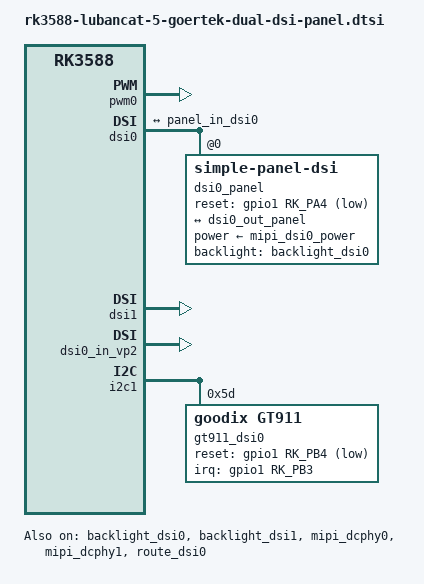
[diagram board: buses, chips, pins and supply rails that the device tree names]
// SPDX-License-Identifier: (GPL-2.0+ OR MIT)
/*
 * Copyright (c) 2021 Rockchip Electronics Co., Ltd.
 *
 */

&pwm0 {
	pinctrl-0 = <&pwm0m0_pins>;
	status = "okay";
};

&backlight_dsi0 {
	status = "okay";
};

&backlight_dsi1 {
	status = "okay";
};

&dsi0 {
	status = "okay";
	//rockchip,data-swap;
	rockchip,dual-channel = <&dsi1>;
    	rockchip,lane-rate = <400000>;
    	
	dsi0_panel: panel@0 {
        	status = "okay";
		compatible = "simple-panel-dsi";
		reg = <0>;
		backlight = <&backlight_dsi0>;
		power-supply = <&mipi_dsi0_power>;
		reset-gpios = <&gpio1 RK_PA4 GPIO_ACTIVE_LOW>;
		bpc = <8>;
		bus-format = <MEDIA_BUS_FMT_RGB888_1X24>;

		enable-delay-ms = <35>;
		prepare-delay-ms = <6>;
		reset-delay-ms = <2000>;
		init-delay-ms = <3000>;
		unprepare-delay-ms = <0>;
		disable-delay-ms = <20>;

		//size,width = <74>;
		//size,height = <133>;

		dsi,flags = <(MIPI_DSI_MODE_VIDEO | MIPI_DSI_MODE_VIDEO_BURST | MIPI_DSI_CLOCK_NON_CONTINUOUS | 
		MIPI_DSI_MODE_LPM)>;
        	dsi,format = <MIPI_DSI_FMT_RGB888>;
        	dsi,lanes  = <8>;

        panel-init-sequence = [

			39 00 02 B0 00
39 00 02 FF 00

39 00 5F F5 12 00 00 89 30 80 0f 00 0d e0 00 18 03 78 03 78 02 00 02 e1 00 20 02 b9 00 0c 00 0d 04 86 02 94 18 00 10 f0 03 0c 20 00 06 0b 0b 33 0e 1c 2a 38 46 54 62 69 70 77 79 7b 7d 7e 01 02 01 00 09 40 09 be 19 fc 19 fa 19 f8 1a 38 1a 78 1a b6 2a b6 2a f4 2a f4 4b 34 63 74 00 00 00 00 00 00
39 00 5F F6 11 00 00 AB 10 A0 0A 00 05 A0 00 20 02 D0 03 84 01 9A 02 68 00 19 02 D9 00 0E 00 0F 03 DF 02 EB 16 00 10 EC 07 10 20 00 06 0F 0F 33 0E 1C 2A 38 46 54 62 69 70 77 79 7B 7D 7E 01 C2 22 00 2A 40 2A BE 3A FC 3A FA 3A F8 3B 38 3B 78 3B 76 4B B6 4B B6 4B F4 63 F4 7C 34 00 00 00 00 00 00
39 00 5F F7 11 00 00 89 10 80 0A 00 05 A0 00 20 02 D0 02 D0 02 00 02 68 00 20 03 87 00 0A 00 0C 03 19 02 63 18 00 10 F0 03 0C 20 00 06 0B 0B 33 0E 1C 2A 38 46 54 62 69 70 77 79 7B 7D 7E 01 02 01 00 09 40 09 BE 19 FC 19 FA 19 F8 1A 38 1A 78 1A B6 2A F6 2B 34 2B 74 3B 74 6B F4 00 00 00 00 00 00
39 00 5F F8 11 00 00 AB 10 A0 0A 00 05 A0 00 20 02 D0 03 84 01 9A 02 68 00 19 02 D9 00 0E 00 0F 03 DF 02 EB 16 00 10 EC 07 10 20 00 06 0F 0F 33 0E 1C 2A 38 46 54 62 69 70 77 79 7B 7D 7E 01 C2 22 00 2A 40 2A BE 3A FC 3A FA 3A F8 3B 38 3B 78 3B 76 4B B6 4B B6 4B F4 63 F4 7C 34 00 00 00 00 00 00
39 00 1C B1 00 18 19 00 18 18 00 18 18 00 18 18 00 18 18 00 18 18 00 18 18 00 18 18 00 18 19
39 00 13 B2 0F 00 0F 00 0F 00 0F 00 0F 00 0F 00 0F 00 0F 00 0F 00
39 00 03 B4 00 BA
39 00 08 B5 11 11 00 01 25 00 EB

39 00 02 B7 93
39 00 02 B8 06
39 00 02 BA 8C
39 00 02 BB 01
39 00 03 BC 00 00
39 00 15 C7 00 00 FF FF 01 03 FF 03 FF 03 FF 00 00 00 00 00 00 00 00 00
39 00 09 C8 10 32 54 76 98 BA DC 0E

39 00 02 FF 01
39 00 15 B1 30 6C 06 FF FF 00 00 48 A3 6B 00 92 03 1A D0 09 00 00 00 08
39 00 04 B2 00 00 00
39 00 BC B5 11 11 10 33 33 33 33 33 FF FF FF 6C 00 00 FF FF FF FF F0 01 00 FB 00 00 00 AA FA 1B 03 20 00 40 00 00 03 10 51 51 10 04 10 03 11 10 04 10 03 10 04 10 03 11 10 03 10 03 00 00 00 00 10 01 10 01 00 00 00 1F FF 00 00 10 01 10 01 00 00 00 1F FF 00 00 00 10 01 10 01 00 80 00 1F FF 00 00 00 10 01 10 01 00 00 00 1F FF 00 00 00 10 01 10 01 00 00 00 1F FF 00 00 10 01 10 01 00 00 00 1F FF 01 00 10 01 10 01 00 00 00 00 00 00 00 10 01 10 01 00 00 00 00 00 00 00 00 00 02 00 00 02 00 00 02 00 00 02 00 00 02 00 00 02 00 00 02 00 00 02 00 00 00 00 00 00 00 00 00 00 00 00
39 00 55 B6 B0 00 00 00 00 00 80 04 0A F0 01 00 00 20 20 00 00 00 00 00 00 00 00 00 00 00 03 05 84 97 8B 00 00 21 00 21 00 21 00 21 00 21 00 21 00 40 00 00 00 00 00 00 00 00 00 00 00 00 00 00 00 00 00 00 00 00 00 00 00 00 03 28 00 14 00 14 00 14 00 14 00 14 00 14
39 00 5D B7 00 00 00 02 00 00 40 05 00 00 88 88 88 88 00 00 00 00 00 00 00 00 00 00 00 00 00 00 00 00 00 00 00 00 00 00 00 00 00 A8 A8 A8 A8 A8 A8 A8 A8 00 FF AA 00 09 10 00 00 00 00 00 00 00 11 11 11 11 11 11 11 11 11 11 11 11 A0 00 00 10 09 C4 01 0A 0A 03 c9 00 00 00 06 7C 28 06 7C 28
39 00 77 BA 00 00 00 00 20 02 6C 10 00 00 00 00 00 00 00 6C 10 00 00 00 00 01 50 17 00 10 00 00 00 00 00 00 00 00 00 00 00 00 00 00 00 00 00 00 00 00 00 00 00 0F FF 00 00 00 00 00 00 00 0F 10 00 10 00 00 00 00 01 B3 20 00 10 00 00 00 00 02 00 00 02 00 00 02 00 00 02 00 00 02 00 00 02 00 00 02 00 00 02 00 00 00 00 00 00 00 00 00 00 00 00 00 00 00 00 00 00 00 00 00
39 00 78 BB 3f fd 00 1f 3f f0 00 03 3f fc 00 0f 3f fc 00 0f 3f fc 00 0f 3f fc 00 0f 3f f0 00 03 3f fc 00 0f 00 00 00 00 00 00 00 00 00 00 00 00 00 00 00 00 00 00 00 00 00 3f fc 00 0f 3f fc 00 0f 3f fc 00 0f 3f fc 00 0f 3f fc 00 0f 3f fc 00 0f 3f fc 00 0f 3f fd 15 5f 3f fc 00 0f 3f fc 00 0f 3f fc 00 0f 3f fc 00 0f 03 c0 00 0f 00 00 48 00 00 01 00 09 3f fc 00 0F 00 00
39 00 21 BE 00 00 00 00 00 07 00 00 00 00 00 00 00 00 00 00 50 AA AA AA AA AA AA 90 00 AA AA AA AA AA AA 90
39 00 8C BF 46 48 4A 4C 4E 50 02 06 0A 0E 12 16 1A 1E 22 2A 01 01 01 01 3C 41 00 00 01 01 33 00 01 01 46 48 4A 4C 4E 50 02 06 0A 0E 12 16 1A 1E 22 2A 01 01 01 01 3C 41 00 00 01 01 33 01 01 01 00 00 00 00 00 00 00 00 00 00 00 00 00 00 00 00 00 00 00 00 00 00 00 00 FF FF FF FF FF FF FF 0F 3F 00 01 00 00 08 C0 0F 00 20 00 00 00 08 00 00 80 00 00 00 00 00 00 00 00 00 00 00 00 00 00 00 00 00 00 00 00 00 00 00 00 00 00 00 00 00 00
39 00 69 C0 03 E8 03 E8 03 E8 00 07 00 07 00 07 03 E8 03 E8 03 E8 00 07 00 07 00 07 03 E8 03 E8 03 E8 00 07 00 07 00 07 03 E8 03 E8 03 E8 00 07 00 07 00 07 00 00 00 29 00 17 00 17 00 17 00 17 00 17 00 17 00 00 00 00 00 00 00 00 00 00 00 00 00 00 00 2B 00 16 00 16 00 16 00 16 00 16 00 08 00 00 00 00 00 00 00 00 00 00 00 00
39 00 54 C2 00 00 BC 00 97 00 97 00 00 00 00 00 00 00 00 00 00 00 5E 00 5E 00 5E 00 5E 00 5E 00 5E 00 5E 00 5E 00 9B 00 9B 00 A3 00 AB 00 31 00 BC 00 31 00 BC 00 0E 00 31 00 0E 00 31 00 84 00 B4 00 00 00 9F 00 00 1F FF 00 00 1F FF 00 26 00 84 00 5E 00 5E 00 00
39 00 AC C3 02 00 14 02 00 14 02 00 14 02 00 14 02 00 14 02 00 14 00 00 12 00 00 12 00 00 12 00 00 12 00 00 12 00 00 12 06 00 24 06 00 24 06 00 24 06 00 24 06 00 24 06 00 24 03 00 28 03 00 28 03 00 28 03 00 28 03 00 28 03 00 28 00 00 00 60 00 24 00 82 00 58 00 99 00 4C 00 AA 00 2E 00 9F 00 26 00 58 00 29 00 84 00 00 00 00 00 00 00 02 00 19 00 21 00 A3 00 AB 00 00 00 00 00 00 00 00 00 00 00 00 00 00 00 00 00 00 00 00 00 00 00 00 00 00 00 00 00 00 00 00 00 00 00 00 00 00 00 00 00 00 00 00 10 00 00 00 00 00 00 00 00 00 00
39 00 2B C4 00 00 00 00 00 00 5E 00 5F 00 7E 00 81 00 57 00 57 00 4B 00 4B 00 28 00 03 00 5A 00 00 00 5E 00 5E 00 5E 00 5E F0 FF FF 7F E7
39 00 0B C5 00 00 00 00 00 00 00 00 08 00
39 00 36 C7 51 C8 C8 C8 C8 C8 C8 C8 C8 C8 00 FF FF FF FF FF FF FF FF FF 4A 48 46 44 42 40 3E 3C 3A 00 FF FF FF FF FF FF FF FF FF FF FF FF FF FF FF FF FF FF 04 04 42 00 88
39 00 44 C8 00 1C FC FC FC 00 00 00 00 00 00 00 00 00 00 00 00 00 00 00 00 00 00 00 00 00 00 00 00 00 00 00 00 00 00 00 00 00 00 00 00 00 00 00 00 00 00 00 00 00 00 00 00 00 00 00 00 00 00 00 00 00 00 00 00 08 08
39 00 44 C9 00 1C FC FC FC 00 00 00 00 00 00 00 00 00 00 00 00 00 00 00 00 00 00 00 00 00 00 00 00 00 00 00 00 00 00 00 00 00 00 00 00 00 00 00 00 00 00 00 00 00 00 00 00 00 00 00 00 00 00 00 00 00 00 00 00 08 08
39 00 44 CA C0 1C FC FC FC 00 00 00 00 00 00 00 00 00 00 00 00 00 00 00 00 00 00 00 00 00 00 00 00 00 00 00 00 00 00 00 00 00 00 00 00 00 00 00 00 00 00 00 00 00 00 00 00 00 00 00 00 00 00 00 00 00 00 00 00 08 08
39 00 3D CB 91 CF ED 52 54 04 32 33 FF FF FF FF FF FF FF FF FF F8 00 00 00 01 01 02 02 03 03 04 04 04 04 04 04 04 04 04 04 04 04 04 0A 0B 0B 0C 0C 0D 0D 0E 0E 0E 0E 0E 0E 0E 0E 0E 0E 0E 0E 0E
39 00 25 CC 8d E0 01 32 32 32 32 32 32 32 32 32 00 49 81 2C 00 40 00 08 0C 00 40 40 00 00 00 00 00 00 00 02 00 FF FF FF
39 00 0F CE 00 00 00 00 00 00 00 00 00 00 00 00 00 00
39 00 13 CF 88 24 00 00 00 00 00 00 00 00 00 00 00 00 00 00 00 00
39 00 B2 D1 0C FF FF FF 00 03 0C 1E 38 5B 89 C0 FF 00 03 0C 1E 38 5B 89 C0 FF 00 03 0C 1E 38 5B 89 C0 FF FF FF FF FF FF FF FF FF FF FF FF FF FF FF FF FF FF FF FF FF FF FF FF FF FF FF FF FF FF FF FF FF FF FF FF 80 80 80 80 80 80 80 80 80 80 80 80 80 80 80 80 80 80 80 80 80 80 80 80 80 80 80 80 80 80 80 80 80 80 80 80 80 80 80 80 80 80 80 80 80 80 80 80 80 80 80 00 00 00 00 00 00 00 00 00 00 00 00 00 00 00 00 00 00 00 00 00 00 00 00 00 00 00 00 00 00 00 00 00 00 00 00 00 00 00 00 00 00 00 00 00 00 00 00 00 00 00 FF FF 00 17 BB 04 38 00 00
39 00 10 D2 2A 00 4D 8B 4D 8B 4D 8B 08 00 08 00 08 00 00
39 00 6A D3 00 40 08 01 00 20 03 00 40 06 00 80 0A 00 C0 0E 01 00 12 01 40 18 01 C0 20 02 40 28 02 C0 30 03 40 38 00 00 40 08 01 00 20 03 00 40 06 00 80 0A 00 C0 0E 01 00 12 01 40 18 01 C0 20 02 40 28 02 C0 30 03 40 38 00 00 40 08 01 00 20 03 00 40 06 00 80 0A 00 C0 0E 01 00 12 01 40 18 01 C0 20 02 40 28 02 C0 30 03 40 38 00
39 00 07 D6 00 FF DF BF 9F 7F
39 00 11 D9 02 0A 0A 0A 0A 0A 0A 00 00 00 00 00 00 00 00 00
39 00 06 DE 14 14 14 2A 02
39 00 3F E1 00 2e 35 07 df df 18 18 0e 1d 0e 0e 0e 0e 1f 1f 37 37 33 33 33 33 F1 00 00 00 00 00 00 00 2E 33 07 DF DF 0E 0E 0E 0E 0E 0E 0E 0E 1F 1F 33 33 33 33 33 33 F1 00 00 00 00 00 00 00 00 00 00
39 00 94 E3 06 11 03 33 33 55 f3 80 94 00 68 00 08 70 10 00 00 00 00 00 00 00 00 00 00 00 00 00 00 00 00 00 00 00 00 00 00 00 00 00 00 00 00 00 00 00 00 00 00 00 00 00 00 00 00 00 00 00 00 00 00 00 00 00 00 00 00 00 00 00 00 00 00 00 00 00 00 00 00 00 00 00 00 00 00 00 00 00 00 00 00 00 00 00 00 00 00 00 00 00 00 00 00 00 00 00 00 00 00 00 00 00 00 00 00 00 00 00 00 00 00 00 00 00 00 00 00 00 00 00 00 00 00 00 00 00 00 00 00 00 00 00 00 00 00 00 00
39 00 1A E4 00 d2 b7 9d 1D 79 04 D2 00 2C 40 00 00 05 1F 1F 1F 1F 1F 1F 00 00 00 00 00
39 00 49 E5 08 08 00 01 00 02 03 01 04 04 05 05 05 05 05 06 06 07 08 02 02 03 0c 10 08 0c 02 10 08 08 08 08 00 00 04 08 1c 1c 1c 08 08 08 08 08 08 08 08 08 08 08 08 08 08 1c 1c 1c 08 04 40 8c cc cc c8 cc cc cc CC CC CC C4 00 00
39 00 06 EA 02 00 00 00 00
39 00 12 EC 60 03 03 12 12 00 57 00 78 08 00 00 01 00 10 00 00
39 00 02 ED 00

39 00 02 FF 03
39 00 3D B1 FF FF FF FF FF FF FF FF FF FF FF FF FF FF FF FF FF FF FF FF FF FF FF FF FF FF FF FF FF FF FF FF FF FF FF FF FF FF FF FF FF FF FF FF FF FF FF FF FF FF FF FF FF FF FF FF FF FF FF FF
39 00 3D B3 22 C2 2C 22 C2 0D 20 D1 EB 1E B1 D3 1D 31 BA 23 C2 3C 23 C2 21 22 12 03 20 31 EF 1E F1 D5 25 E2 5E 25 E2 47 24 72 33 23 32 25 22 52 18 23 C2 3C 23 C2 21 22 12 03 20 31 EF 1E F1 D5
39 00 3D B4 33 23 32 33 23 32 33 23 32 33 23 32 33 23 32 33 23 32 33 23 32 33 23 32 33 23 32 33 23 32 33 23 32 33 23 32 33 23 32 33 23 32 33 23 32 33 23 32 33 23 32 33 23 32 33 23 32 33 23 32
39 00 3D B6 00 00 00 00 00 00 00 00 00 00 00 00 00 00 00 00 00 00 00 00 00 00 00 00 00 00 00 33 3F FF 00 00 00 00 00 00 00 00 00 00 00 00 00 00 00 00 00 00 00 00 00 00 00 00 00 00 00 33 3F FF
39 00 72 C0 00 04 80 49 04 B0 4F 05 3A 58 36 0A 67 D6 EB 74 C7 91 7D 08 09 84 18 A1 90 09 4B 98 D9 D2 A1 8A 53 A9 3A D2 B4 C0 00 45 A4 6A 48 A4 CA 50 B5 58 5D A6 4C 6B C7 1D 76 B7 B5 7F 78 30 8A 49 03 95 D9 A9 9F 1A 39 A8 0A C2 B0 3B 81 00 04 6D 48 54 B5 51 55 7F 5D A6 65 6D 97 36 78 27 C5 7F D8 34 86 38 C2 91 39 60 9A 69 EC A2 FA 70 AA FA ED B6 80
39 00 72 C1 00 04 75 48 94 B1 50 15 5E 5A A6 3D 6B C7 27 78 27 CC 80 A8 44 88 38 E8 94 39 91 9D CA 24 A6 BA B0 AF DB 36 BC 10 00 46 F4 7F 49 F4 DF 52 B5 78 60 86 88 6F 67 5B 7B 17 F9 83 48 7C 8E E9 54 9A C9 FE A4 CA 9C AE 8B 31 B7 5C 0A 00 04 73 48 F4 C7 53 75 A7 60 26 97 70 C7 66 7B 57 FA 83 68 6D 8A 19 02 95 A9 AB 9F 8A 43 A8 9A D2 B1 8B 5B BE 40
39 00 72 C2 00 04 84 49 84 C0 51 05 66 5C 36 51 6D A7 4A 79 E7 E7 82 D8 6B 8A 39 0C 96 39 B8 A0 AA 56 A9 BA E7 B2 EB 78 C0 A0 00 47 C4 8C 4A C4 EC 53 95 8E 62 06 A8 71 A7 7B 7D 28 10 86 48 A6 91 89 79 9D 6A 2B A7 EA CE B1 DB 6D BB 6C 4D 00 04 83 49 F4 D7 54 75 BE 61 B6 B1 72 67 81 7C F8 13 84 D8 8C 8C 49 23 97 A9 D2 A2 4A 71 AB EB 07 B5 1B 9B C3 D0
39 00 72 C3 00 04 97 4A B4 D3 52 35 7B 5D D6 70 6F 67 63 7C 18 0A 84 C8 8F 8C B9 39 99 49 E3 A3 BA 8F AD 7B 26 B7 5B C4 C6 60 00 46 D4 81 4A 94 F9 54 E5 AD 64 16 C7 73 E7 A8 7F 58 42 88 C8 CC 94 29 AF A0 AA 66 AB CB 10 B6 2B B5 C0 5C B0 00 04 94 4B 04 E8 55 85 D1 63 66 CE 73 E7 9F 7F 08 36 87 68 B1 8E 69 4C 9A DA 02 A5 6A AA AF BB 4A B9 8B EB C8 F0
39 00 72 C4 00 04 83 49 B4 CB 52 B5 95 5E A6 93 71 C7 83 7D A8 2C 87 18 B7 8F 29 58 9B 2A 12 A6 2A BB B1 0B 61 BA FC 04 CC 10 00 45 A4 72 4A 25 02 56 65 B5 65 E6 E9 76 07 C0 81 88 6B 8B 38 F2 96 C9 DA A3 9A 94 AE CB 46 B9 CB F5 C4 9D 10 00 04 A6 4C 24 FA 56 A5 E8 64 86 E6 75 C7 B9 80 98 4F 89 28 CF 90 89 6F 9D 0A 2D A8 2A DE B2 EB 83 BD 7C 2E CE C0
39 00 72 C5 00 01 AF 31 93 7F 3E 84 33 47 14 CF 53 55 7C 5B F6 03 64 46 BB 72 A7 95 80 28 73 8E 89 67 9F 4A 82 B2 2B DB CA 90 00 00 52 70 2D 93 3B 39 63 E4 45 04 C4 51 B5 6E 5B F6 0B 69 27 0F 78 57 F7 86 D8 E3 96 09 EA A7 3B 0E BC 0C 7D 00 00 5A 19 62 21 2B D3 4B 3C 14 5F 4E 35 3F 59 35 E3 62 D6 B0 72 87 9A 80 D8 81 8F 69 73 9F FA 88 B2 3B D2 C9 00
39 00 72 C6 00 01 AF 31 93 7F 3E 84 33 47 14 CF 53 55 7C 5B F6 03 64 46 BB 72 A7 95 80 28 73 8E 89 67 9F 4A 82 B2 2B DB CA 90 00 00 52 70 2D 93 3B 39 63 E4 45 04 C4 51 B5 6E 5B F6 0B 69 27 0F 78 57 F7 86 D8 E3 96 09 EA A7 3B 0E BC 0C 7D 00 00 5A 19 62 21 2B D3 4B 3C 14 5F 4E 35 3F 59 35 E3 62 D6 B0 72 87 9A 80 D8 81 8F 69 73 9F FA 88 B2 3B D2 C9 00
39 00 72 C7 00 01 AF 31 93 7F 3E 84 33 47 14 CF 53 55 7C 5B F6 03 64 46 BB 72 A7 95 80 28 73 8E 89 67 9F 4A 82 B2 2B DB CA 90 00 00 52 70 2D 93 3B 39 63 E4 45 04 C4 51 B5 6E 5B F6 0B 69 27 0F 78 57 F7 86 D8 E3 96 09 EA A7 3B 0E BC 0C 7D 00 00 5A 19 62 21 2B D3 4B 3C 14 5F 4E 35 3F 59 35 E3 62 D6 B0 72 87 9A 80 D8 81 8F 69 73 9F FA 88 B2 3B D2 C9 00
39 00 72 C8 00 01 AF 31 93 7F 3E 84 33 47 14 CF 53 55 7C 5B F6 03 64 46 BB 72 A7 95 80 28 73 8E 89 67 9F 4A 82 B2 2B DB CA 90 00 00 52 70 2D 93 3B 39 63 E4 45 04 C4 51 B5 6E 5B F6 0B 69 27 0F 78 57 F7 86 D8 E3 96 09 EA A7 3B 0E BC 0C 7D 00 00 5A 19 62 21 2B D3 4B 3C 14 5F 4E 35 3F 59 35 E3 62 D6 B0 72 87 9A 80 D8 81 8F 69 73 9F FA 88 B2 3B D2 C9 00
39 00 72 C9 00 01 AF 31 93 7F 3E 84 33 47 14 CF 53 55 7C 5B F6 03 64 46 BB 72 A7 95 80 28 73 8E 89 67 9F 4A 82 B2 2B DB CA 90 00 00 52 70 2D 93 3B 39 63 E4 45 04 C4 51 B5 6E 5B F6 0B 69 27 0F 78 57 F7 86 D8 E3 96 09 EA A7 3B 0E BC 0C 7D 00 00 5A 19 62 21 2B D3 4B 3C 14 5F 4E 35 3F 59 35 E3 62 D6 B0 72 87 9A 80 D8 81 8F 69 73 9F FA 88 B2 3B D2 C9 00
39 00 72 CA 00 02 B2 2C A2 FA 35 A3 BC 40 D4 C0 53 B5 A5 60 06 58 6A 16 EA 72 27 94 7E D8 45 89 38 DD 91 E9 5E 99 C9 D4 A4 A0 00 2A 72 BB 2E 33 33 38 73 D1 46 E4 F0 55 D5 BD 61 26 61 6A B6 EC 76 37 C6 82 38 76 8C C9 15 95 A9 9E 9D FA 60 00 02 60 28 02 C0 34 03 C6 43 D5 01 58 25 EA 64 36 93 6D 67 13 74 97 AA 7F B8 4C 89 48 D7 91 79 56 99 19 CD A4 00
39 00 72 CB 00 02 CD 2E 53 15 37 53 DB 44 34 EF 57 45 E9 64 B6 A0 6F 07 31 76 F7 E0 84 18 97 8E 99 35 97 C9 C3 A0 2A 45 AC B0 00 2B F2 D3 2F B3 4B 3A 23 FE 49 F5 27 59 C6 04 65 96 B1 6F B7 3C 7B 48 1B 87 E8 D7 92 B9 78 9C 2A 08 A5 2A E0 00 02 62 28 62 CE 35 E3 F2 47 95 35 5B D6 27 68 56 D0 71 57 52 78 A7 EE 84 78 97 8E 39 2C 97 09 B2 9F 3A 35 AB 90
39 00 72 CC 00 02 DC 2F 43 24 38 43 EF 45 75 08 59 36 02 66 E6 C8 70 E7 56 79 57 FF 86 88 C3 91 29 61 9A 99 F2 A3 7A 80 B0 C0 00 2C B2 DF 30 73 57 3B 44 13 4C 35 4C 5B F6 26 68 56 D3 71 E7 60 7D 88 4B 8A C9 09 95 C9 AD 9F AA 44 A9 1B 23 00 02 79 29 D2 E5 37 54 0D 49 25 52 5D 86 47 6A 26 F3 73 47 73 7A B8 0F 86 A8 C2 90 B9 57 9A 09 E5 A2 BA 6F AF 60
39 00 72 CD 00 02 CD 2E 93 21 39 14 04 47 35 29 5B B6 2E 69 56 F3 74 17 86 7C 58 35 89 98 F8 94 B9 9B 9E 8A 34 A8 2A CF B6 50 00 2B 92 D1 30 13 61 3C B4 2B 4E 15 74 5E 86 50 6B 27 05 75 17 96 81 08 81 8E 99 44 99 B9 F0 A4 3A 92 AE 4B 85 00 02 76 29 E2 EE 38 E4 30 4B 45 77 5F C6 6E 6C 87 16 75 E7 9B 7D 58 3B 89 98 F0 94 39 91 9D 9A 28 A7 2A BC B5 20
39 00 72 CE 00 02 DB 2F 73 2F 39 F4 17 48 F5 49 5D 36 50 6B B7 0C 75 C7 A2 7E 08 53 8C 29 1C 97 29 C8 A1 3A 68 AB 8B 08 BA E0 00 2C 52 DD 30 D3 6D 3D 94 48 4F E5 8B 60 76 76 6D 17 25 77 47 BA 83 68 AA 91 19 6F 9C BA 20 A7 8A CC B1 DB CF 00 02 8A 2B 23 02 3A 24 49 4D 05 8D 61 46 89 6E 57 33 77 97 B7 7F 08 5B 8B E9 14 96 99 BA A0 8A 58 AA 8A F5 B9 70
39 00 72 CF 00 01 AF 31 93 7F 3E 84 33 47 14 CF 53 55 7C 5B F6 03 64 46 BB 72 A7 95 80 28 73 8E 89 67 9F 4A 82 B2 2B DB CA 90 00 00 52 70 2D 93 3B 39 63 E4 45 04 C4 51 B5 6E 5B F6 0B 69 27 0F 78 57 F7 86 D8 E3 96 09 EA A7 3B 0E BC 0C 7D 00 00 5A 19 62 21 2B D3 4B 3C 14 5F 4E 35 3F 59 35 E3 62 D6 B0 72 87 9A 80 D8 81 8F 69 73 9F FA 88 B2 3B D2 C9 00
39 00 72 D0 00 01 AF 31 93 7F 3E 84 33 47 14 CF 53 55 7C 5B F6 03 64 46 BB 72 A7 95 80 28 73 8E 89 67 9F 4A 82 B2 2B DB CA 90 00 00 52 70 2D 93 3B 39 63 E4 45 04 C4 51 B5 6E 5B F6 0B 69 27 0F 78 57 F7 86 D8 E3 96 09 EA A7 3B 0E BC 0C 7D 00 00 5A 19 62 21 2B D3 4B 3C 14 5F 4E 35 3F 59 35 E3 62 D6 B0 72 87 9A 80 D8 81 8F 69 73 9F FA 88 B2 3B D2 C9 00
39 00 72 D1 00 01 AF 31 93 7F 3E 84 33 47 14 CF 53 55 7C 5B F6 03 64 46 BB 72 A7 95 80 28 73 8E 89 67 9F 4A 82 B2 2B DB CA 90 00 00 52 70 2D 93 3B 39 63 E4 45 04 C4 51 B5 6E 5B F6 0B 69 27 0F 78 57 F7 86 D8 E3 96 09 EA A7 3B 0E BC 0C 7D 00 00 5A 19 62 21 2B D3 4B 3C 14 5F 4E 35 3F 59 35 E3 62 D6 B0 72 87 9A 80 D8 81 8F 69 73 9F FA 88 B2 3B D2 C9 00
39 00 72 D2 00 01 AF 31 93 7F 3E 84 33 47 14 CF 53 55 7C 5B F6 03 64 46 BB 72 A7 95 80 28 73 8E 89 67 9F 4A 82 B2 2B DB CA 90 00 00 52 70 2D 93 3B 39 63 E4 45 04 C4 51 B5 6E 5B F6 0B 69 27 0F 78 57 F7 86 D8 E3 96 09 EA A7 3B 0E BC 0C 7D 00 00 5A 19 62 21 2B D3 4B 3C 14 5F 4E 35 3F 59 35 E3 62 D6 B0 72 87 9A 80 D8 81 8F 69 73 9F FA 88 B2 3B D2 C9 00
39 00 72 D3 00 01 AF 31 93 7F 3E 84 33 47 14 CF 53 55 7C 5B F6 03 64 46 BB 72 A7 95 80 28 73 8E 89 67 9F 4A 82 B2 2B DB CA 90 00 00 52 70 2D 93 3B 39 63 E4 45 04 C4 51 B5 6E 5B F6 0B 69 27 0F 78 57 F7 86 D8 E3 96 09 EA A7 3B 0E BC 0C 7D 00 00 5A 19 62 21 2B D3 4B 3C 14 5F 4E 35 3F 59 35 E3 62 D6 B0 72 87 9A 80 D8 81 8F 69 73 9F FA 88 B2 3B D2 C9 00

39 00 02 FF 01
39 00 02 EC 20
39 00 02 FF 00
39 00 0F 3B 00 08 00 08 00 00 06 18 05 A0 04 C8 03 A0
39 00 02 03 01
39 00 02 26 01
39 00 03 44 00 00
39 00 02 35 00
39 00 02 36 02
39 00 03 51 FF FF
39 00 02 53 20
39 00 02 64 00
39 00 02 65 90

39 00 02 FF 01
39 00 02 B0 04

39 00 03 C5 02 03	

39 00 72 F5 
12 00 00 AB 30 80 0B 40 
0A 68 05 A0 02 9A 02 9A 
02 00 02 A1 00 20 85 EE 
00 09 00 0F 00 16 00 0F 
18 00 10 F0 07 10 20 00 
06 0F 0F 33 0E 1C 2A 38 
46 54 62 69 70 77 79 7B 
7D 7E 02 02 22 00 2A 40 
2A BE 3A FC 3A FA 3A F8 
3B 38 3B 78 3B B6 4B B6 
4B F4 4B F4 6C 34 84 74  
00 00 00 00 00 00 00 00 
00 00 00 00 00 00 00 00 
00 00 00 00 00 00 00 00 
00

39 00 02 FF 00
39 00 02 B0 00             


05 78 01 29

//bist code
//39 00 02 FF 00
//39 00 02 36 00
//39 00 06 C8 12 32 54 76 0F
//39 00 15 C7 01 38 FF FF 01 03 FF 03 FF 03 FF 00 00 00 00 00 00 00 00 00

05 78 01 11

0A 00 80
12 00 00 AB 30 80 0B 40 
0A 68 05 A0 02 9A 02 9A 
02 00 02 A1 00 20 85 EE 
00 09 00 0F 00 16 00 0F 
18 00 10 F0 07 10 20 00 
06 0F 0F 33 0E 1C 2A 38 
46 54 62 69 70 77 79 7B 
7D 7E 02 02 22 00 2A 40 
2A BE 3A FC 3A FA 3A F8 
3B 38 3B 78 3B B6 4B B6 
4B F4 4B F4 6C 34 84 74  
00 00 00 00 00 00 00 00 
00 00 00 00 00 00 00 00 
00 00 00 00 00 00 00 00 
00 00 00 00 00 00 00 00 
00 00 00 00 00 00 00 00
                      
        ];

		panel-exit-sequence = [
			05 78 01 28
			05 00 01 10
		];
		
		compressed-data;
        	slice-width = <666>;
        	slice-height = <1440>;
        	version-major = <1>;
        	version-minor = <1>;

		disp0_timings0: display-timings {
			native-mode = <&dsi0_timing0>;
			dsi0_timing0: timing0 {
				clock-frequency = <285000000>;
				hactive = <2664>;
				vactive = <2880>;
				hback-porch = <200>;
				hfront-porch = <400>;
				hsync-len = <4>;
				vback-porch = <10>;
				vfront-porch = <30>;
				vsync-len = <1>;
				hsync-active = <0>;
				vsync-active = <0>;
				de-active = <0>;
				pixelclk-active = <0>;
			};
		};

		ports {
			#address-cells = <1>;
			#size-cells = <0>;
			port@0 {
				reg = <0>;
				panel_in_dsi0: endpoint {
					remote-endpoint = <&dsi0_out_panel>;
				};
			};
		};
	};

	ports {
		#address-cells = <1>;
		#size-cells = <0>;

		port@1 {
			reg = <1>;
			dsi0_out_panel: endpoint {
				remote-endpoint = <&panel_in_dsi0>;
			};
		};
	};
};

&dsi1 {
    status = "okay";
};

&dsi0_in_vp2 {
	status = "okay";
};

&mipi_dcphy0 {
	status = "okay";
};

&mipi_dcphy1 {
	status = "okay";
};

&route_dsi0 {
	status = "okay";
	connect = <&vp2_out_dsi0>;
};

&i2c1 {
	status = "okay";
	pinctrl-names = "default";
	pinctrl-0 = <&i2c1m2_xfer>;

	gt911_dsi0: gt911@5d {
		status = "okay";
		compatible = "goodix,gt911";
		reg = <0x5d>;
		interrupt-parent = <&gpio1>;
		interrupts = <RK_PB3 IRQ_TYPE_LEVEL_LOW>;
		reset-gpios = <&gpio1 RK_PB4 GPIO_ACTIVE_LOW>;
		irq-gpios = <&gpio1 RK_PB3 GPIO_ACTIVE_HIGH>;
		touchscreen-inverted-x = <1>;
		touchscreen-inverted-y = <1>;
	};
};
